# ESP32-S3-ULP register map
Vendor: ESPRESSIF SYSTEMS (SHANGHAI) CO., LTD.; Series: RISC-V ULP; File version: 2
32-bit RISC-V MCU
CPU: RV32IMC r0p0, little endian, no MPU, no FPU, 0 interrupt priority bits
Address unit: 32 bits
Registers are 32-bit, read-write, reset 0x0 unless marked. A register's access mark holds for its fields unless they carry their own. Offsets are from the block's base; lines under a group give offsets from that group; [hi:lo] are bit positions; {n}, {i} and the like mark numbered series; 'fields as' and 'values as' point back to an identical list; <NAME> marks a mode.

## Memory map
0x00008000 RTC_CNTL size 0x15C — Real-Time Clock Control
0x0000A400 RTC_IO size 0xF0 — Low-power Input/Output
0x0000C800 SENS size 0x11C — SENS Peripheral
0x0000EC00 RTC_I2C size 0x7C — Low-power I2C (Inter-Integrated Circuit) Controller

## Interrupts
0 TOUCH_DONE_INT (SENS)
1 TOUCH_INACTIVE_INT (SENS)
2 TOUCH_ACTIVE_INT (SENS)
3 SARADC1_DONE_INT (SENS)
4 SARADC2_DONE_INT (SENS)
5 TSENS_DONE_INT (SENS)
6 RISCV_START_INT (RTC_CNTL)
7 SW_INT (RTC_CNTL)
8 SWD_INT (RTC_CNTL)
9 TOUCH_TIME_OUT_INT (SENS)
10 TOUCH_APPROACH_LOOP_DONE_INT (SENS)
11 TOUCH_SCAN_DONE_INT (SENS)
12 GPIO_INT (RTC_IO)

## RTC_IO — Low-power Input/Output
Base 0x0000A400
0x00 RTC_GPIO_OUT — RTC GPIO 0 ~ 21 output data register
  [31:10] DATA — RTC GPIO 0 ~ 21 output data
0x04 RTC_GPIO_OUT_W1TS wo — one set RTC GPIO output data
  [31:10] RTC_GPIO_OUT_DATA_W1TS — RTC GPIO 0 ~ 21 output data write 1 to set
0x08 RTC_GPIO_OUT_W1TC wo — one clear RTC GPIO output data
  [31:10] RTC_GPIO_OUT_DATA_W1TC — RTC GPIO 0 ~ 21 output data write 1 to clear
0x0C RTC_GPIO_ENABLE — Configure RTC GPIO output enable
  [31:10] RTC_GPIO_ENABLE — RTC GPIO 0 ~ 21 enable
0x10 RTC_GPIO_ENABLE_W1TS wo — one set RTC GPIO output enable
  [31:10] RTC_GPIO_ENABLE_W1TS — RTC GPIO 0 ~ 21 enable write 1 to set
0x14 RTC_GPIO_ENABLE_W1TC wo — one clear RTC GPIO output enable
  [31:10] RTC_GPIO_ENABLE_W1TC — RTC GPIO 0 ~ 21 enable write 1 to clear
0x18 RTC_GPIO_STATUS — RTC GPIO 0 ~ 21 interrupt status
  [31:10] INT
0x1C RTC_GPIO_STATUS_W1TS wo — One set RTC GPIO 0 ~ 21 interrupt status
  [31:10] RTC_GPIO_STATUS_INT_W1TS — RTC GPIO 0 ~ 21 interrupt status write 1 to set
0x20 RTC_GPIO_STATUS_W1TC wo — One clear RTC GPIO 0 ~ 21 interrupt status
  [31:10] RTC_GPIO_STATUS_INT_W1TC — RTC GPIO 0 ~ 21 interrupt status write 1 to clear
0x24 RTC_GPIO_IN ro — RTC GPIO input data
  [31:10] NEXT
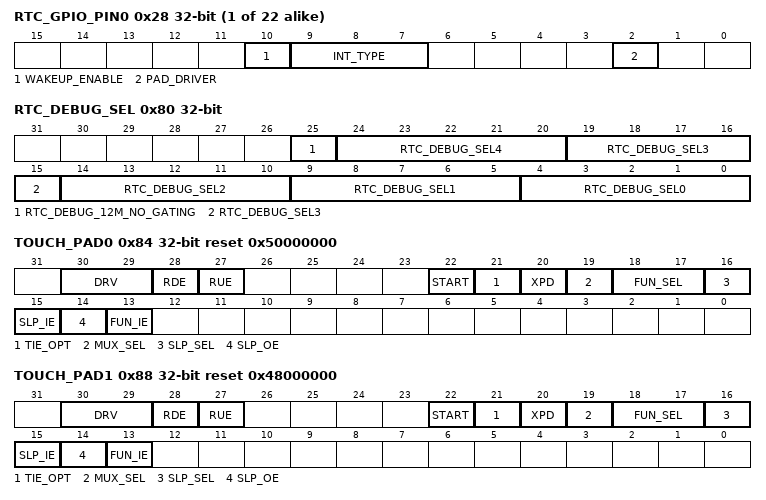
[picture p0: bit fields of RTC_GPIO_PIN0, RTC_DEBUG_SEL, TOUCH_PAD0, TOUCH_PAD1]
{0x28+4i} RTC_GPIO_PIN{i} (i=0..21) — configure RTC GPIO{i}
  [10] WAKEUP_ENABLE — RTC GPIO wakeup enable bit
  [9:7] INT_TYPE — if set to 0: GPIO interrupt disable, if set to 1: rising edge trigger, if set to 2: falling edge trigger, if set to 3: any edge trigger, if set to 4: low level trigger, if set to 5: high level trigger
  [2] PAD_DRIVER — if set to 0: normal output, if set to 1: open drain
0x80 RTC_DEBUG_SEL — configure rtc debug
  [25] RTC_DEBUG_12M_NO_GATING — configure rtc debug
  [5n+4:5n] RTC_DEBUG_SEL{n} (n=0..4) — configure rtc debug
0x84 TOUCH_PAD0 reset 0x50000000 — configure RTC PAD0
  [30:29] DRV
  [28] RDE
  [27] RUE
  [22] START — TOUCH_START
  [21] TIE_OPT — TOUCH_TIE_OPT
  [20] XPD — TOUCH_XPD
  [19] MUX_SEL — 1: use RTC GPIO,0: use digital GPIO
  [18:17] FUN_SEL — function sel
  [16] SLP_SEL — 1: enable sleep mode during sleep,0: no sleep mode
  [15] SLP_IE — input enable in sleep mode
  [14] SLP_OE — output enable in sleep mode
  [13] FUN_IE — input enable in work mode
0x88 TOUCH_PAD1 reset 0x48000000 — configure RTC PAD1
  fields as TOUCH_PAD0
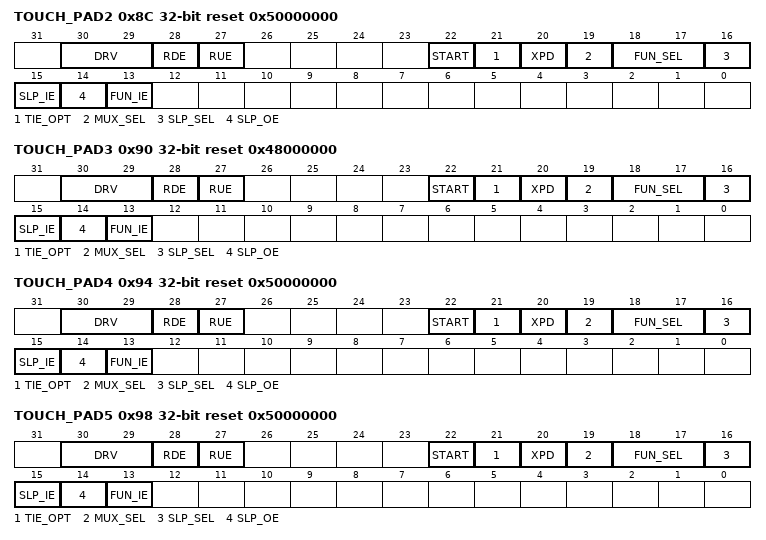
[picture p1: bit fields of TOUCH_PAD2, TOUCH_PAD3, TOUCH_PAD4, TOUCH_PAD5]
0x8C TOUCH_PAD2 reset 0x50000000 — configure RTC PAD2
  fields as TOUCH_PAD0
0x90 TOUCH_PAD3 reset 0x48000000 — configure RTC PAD3
  fields as TOUCH_PAD0
0x94 TOUCH_PAD4 reset 0x50000000 — configure RTC PAD4
  fields as TOUCH_PAD0
0x98 TOUCH_PAD5 reset 0x50000000 — configure RTC PAD5
  fields as TOUCH_PAD0
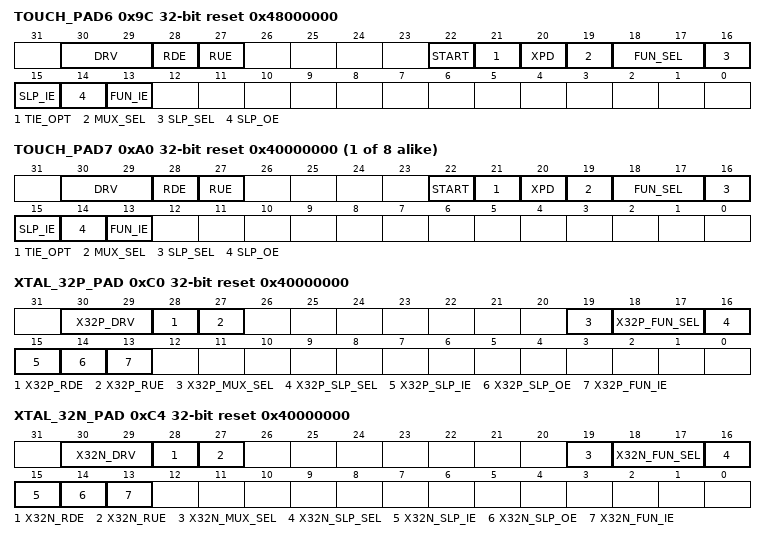
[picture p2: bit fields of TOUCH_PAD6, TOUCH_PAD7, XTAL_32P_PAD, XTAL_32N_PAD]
0x9C TOUCH_PAD6 reset 0x48000000 — configure RTC PAD6
  fields as TOUCH_PAD0
{0x84+4i} TOUCH_PAD{i} reset 0x40000000 (i=7..14) — configure RTC PAD{i}
  fields as TOUCH_PAD0
0xC0 XTAL_32P_PAD reset 0x40000000 — configure RTC PAD15
  [30:29] X32P_DRV — DRV
  [28] X32P_RDE — RDE
  [27] X32P_RUE — RUE
  [19] X32P_MUX_SEL — 1: use RTC GPIO,0: use digital GPIO
  [18:17] X32P_FUN_SEL — function sel
  [16] X32P_SLP_SEL — 1: enable sleep mode during sleep,0: no sleep mode
  [15] X32P_SLP_IE — input enable in sleep mode
  [14] X32P_SLP_OE — output enable in sleep mode
  [13] X32P_FUN_IE — input enable in work mode
0xC4 XTAL_32N_PAD reset 0x40000000 — configure RTC PAD16
  [30:29] X32N_DRV — DRV
  [28] X32N_RDE — RDE
  [27] X32N_RUE — RUE
  [19] X32N_MUX_SEL — 1: use RTC GPIO,0: use digital GPIO
  [18:17] X32N_FUN_SEL — function sel
  [16] X32N_SLP_SEL — 1: enable sleep mode during sleep,0: no sleep mode
  [15] X32N_SLP_IE — input enable in sleep mode
  [14] X32N_SLP_OE — output enable in sleep mode
  [13] X32N_FUN_IE — input enable in work mode
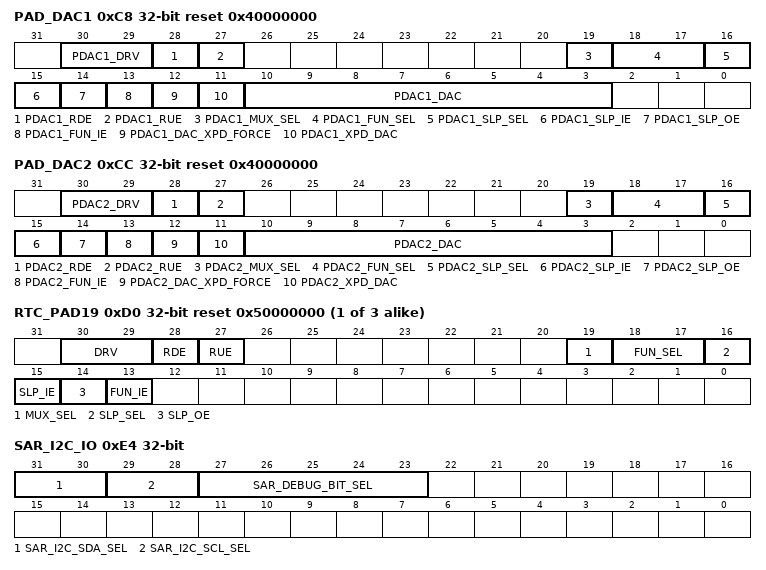
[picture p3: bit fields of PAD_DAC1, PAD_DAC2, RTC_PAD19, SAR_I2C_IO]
0xC8 PAD_DAC1 reset 0x40000000 — configure RTC PAD17
  [30:29] PDAC1_DRV
  [28] PDAC1_RDE
  [27] PDAC1_RUE
  [19] PDAC1_MUX_SEL — 1: use RTC GPIO,0: use digital GPIO
  [18:17] PDAC1_FUN_SEL — PDAC1 function sel
  [16] PDAC1_SLP_SEL — 1: enable sleep mode during sleep,0: no sleep mode
  [15] PDAC1_SLP_IE — input enable in sleep mode
  [14] PDAC1_SLP_OE — output enable in sleep mode
  [13] PDAC1_FUN_IE — input enable in work mode
  [12] PDAC1_DAC_XPD_FORCE — 1: use reg_pdac1_xpd_dac to control PDAC1_XPD_DAC,0: use SAR ADC FSM to control PDAC1_XPD_DAC
  [11] PDAC1_XPD_DAC
  [10:3] PDAC1_DAC
0xCC PAD_DAC2 reset 0x40000000 — configure RTC PAD18
  [30:29] PDAC2_DRV
  [28] PDAC2_RDE
  [27] PDAC2_RUE
  [19] PDAC2_MUX_SEL — 1: use RTC GPIO,0: use digital GPIO
  [18:17] PDAC2_FUN_SEL — PDAC1 function sel
  [16] PDAC2_SLP_SEL — 1: enable sleep mode during sleep,0: no sleep mode
  [15] PDAC2_SLP_IE — input enable in sleep mode
  [14] PDAC2_SLP_OE — output enable in sleep mode
  [13] PDAC2_FUN_IE — input enable in work mode
  [12] PDAC2_DAC_XPD_FORCE — 1: use reg_pdac2_xpd_dac to control PDAC2_XPD_DAC,0: use SAR ADC FSM to control PDAC2_XPD_DAC
  [11] PDAC2_XPD_DAC
  [10:3] PDAC2_DAC
{0x84+4i} RTC_PAD{i} reset 0x50000000 (i=19..21) — configure RTC PAD{i}
  [30:29] DRV
  [28] RDE
  [27] RUE
  [19] MUX_SEL — 1: use RTC GPIO,0: use digital GPIO
  [18:17] FUN_SEL — function sel
  [16] SLP_SEL — 1: enable sleep mode during sleep,0: no sleep mode
  [15] SLP_IE — input enable in sleep mode
  [14] SLP_OE — output enable in sleep mode
  [13] FUN_IE — input enable in work mode
0xDC EXT_WAKEUP0 — configure EXT0 wakeup
  [31:27] SEL — ******* Description configure***
0xE0 XTL_EXT_CTR — configure gpio pd XTAL
  [31:27] SEL — select RTC GPIO 0 ~ 17 to control XTAL
0xE4 SAR_I2C_IO — configure rtc i2c mux
  [31:30] SAR_I2C_SDA_SEL — ******* Description configure***
  [29:28] SAR_I2C_SCL_SEL — ******* Description configure***
  [27:23] SAR_DEBUG_BIT_SEL — ******* Description configure***
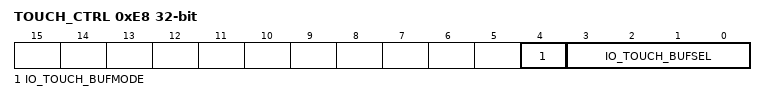
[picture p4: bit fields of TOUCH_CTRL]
0xE8 TOUCH_CTRL — configure touch pad bufmode
  [4] IO_TOUCH_BUFMODE — BUF_MODE when touch work without fsm
  [3:0] IO_TOUCH_BUFSEL — BUF_SEL when touch work without fsm
0x1FC DATE reset 0x2101180 — version
  [27:0] DATE

## Licence text in the file
Copyright 2025 Espressif Systems (Shanghai) PTE LTD Licensed under the Apache License, Version 2.0 (the "License"); you may not use this file except in compliance with the License. You may obtain a copy of the License at http://www.apache.org/licenses/LICENSE-2.0 Unless required by applicable law or agreed to in writing, software distributed under the License is distributed on an "AS IS" BASIS, WITHOUT WARRANTIES OR CONDITIONS OF ANY KIND, either express or implied. See the License for the specific language governing permissions and limitations under the License.
